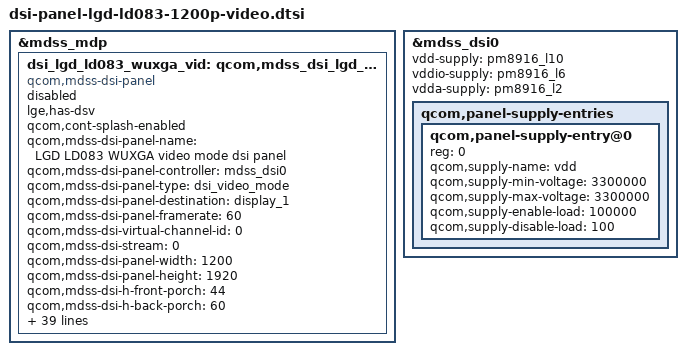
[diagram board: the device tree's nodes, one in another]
&mdss_mdp {
	dsi_lgd_ld083_wuxga_vid: qcom,mdss_dsi_lgd_ld083_wuxga_video{
		lge,has-dsv;
		compatible = "qcom,mdss-dsi-panel";
		status = "disable";
		qcom,cont-splash-enabled;
		qcom,mdss-dsi-panel-name = "LGD LD083 WUXGA video mode dsi panel";
		qcom,mdss-dsi-panel-controller = <&mdss_dsi0>;
		qcom,mdss-dsi-panel-type = "dsi_video_mode";
		qcom,mdss-dsi-panel-destination = "display_1";
		qcom,mdss-dsi-panel-framerate = <60>;
		qcom,mdss-dsi-virtual-channel-id = <0>;
		qcom,mdss-dsi-stream = <0>;
		qcom,mdss-dsi-panel-width = <1200>;
		qcom,mdss-dsi-panel-height = <1920>;
		qcom,mdss-dsi-h-front-porch = <44>;
		qcom,mdss-dsi-h-back-porch = <60>;
		qcom,mdss-dsi-h-pulse-width = <32>;
		qcom,mdss-dsi-h-sync-skew = <0>;
		qcom,mdss-dsi-v-back-porch = <10>;
		qcom,mdss-dsi-v-front-porch = <5>;
		qcom,mdss-dsi-v-pulse-width = <5>;
		qcom,mdss-dsi-h-left-border = <0>;
		qcom,mdss-dsi-h-right-border = <0>;
		qcom,mdss-dsi-v-top-border = <0>;
		qcom,mdss-dsi-v-bottom-border = <0>;
		qcom,mdss-pan-physical-width-dimension = < 111 >;
		qcom,mdss-pan-physical-height-dimension = < 178 >;
		qcom,mdss-dsi-bpp = <24>;
		qcom,mdss-dsi-color-order = "rgb_swap_rgb";
		qcom,mdss-dsi-underflow-color = <0xff>;
		qcom,mdss-dsi-border-color = <0>;
		qcom,mdss-dsi-on-command = [
			05 01 00 00 10 00 02
			11 00
			05 01 00 00 05 00 02
			29 00
		];
		lge,display-on-cmds = [
			05 01 00 00 10 00 02
			11 00
			05 01 00 00 05 00 02
			29 00
		];
		qcom,mdss-dsi-off-command = [
			05 01 00 00 05 00 02
			28 00
			05 01 00 00 0A 00 02
			10 00
		];
		qcom,mdss-dsi-on-command-state = "dsi_lp_mode";
		qcom,mdss-dsi-off-command-state = "dsi_hs_mode";
		qcom,mdss-dsi-h-sync-pulse = <0>;
		qcom,mdss-dsi-traffic-mode = "non_burst_sync_event";
		qcom,mdss-dsi-lane-map = "lane_map_0123";
		//qcom,mdss-dsi-hfp-power-mode;
		//qcom,mdss-dsi-hbp-power-mode;
		//qcom,mdss-dsi-hsa-power-mode;
		qcom,mdss-dsi-bllp-eof-power-mode;
		//qcom,mdss-dsi-bllp-power-mode;
		qcom,mdss-dsi-lane-0-state;
		qcom,mdss-dsi-lane-1-state;
		qcom,mdss-dsi-lane-2-state;
		qcom,mdss-dsi-lane-3-state;
		qcom,mdss-dsi-panel-timings = [EF 3A 28 00 6C FF 54 3E 61 03 04 00];
		qcom,mdss-dsi-t-clk-post = <0x02>;
		qcom,mdss-dsi-t-clk-pre = <0x32>;
		//qcom,mdss-dsi-bl-min-level = <1>;
		//qcom,mdss-dsi-bl-max-level = <4095>;
		qcom,mdss-dsi-dma-trigger = "trigger_sw";
		qcom,mdss-dsi-mdp-trigger = "none";
		//qcom,mdss-dsi-bl-pmic-control-type = "bl_ctrl_wled";
		qcom,mdss-dsi-reset-sequence = <1 20>, <0 20>, <1 20>;
	};
};


&mdss_dsi0 {
	vdd-supply = <&pm8916_l10>;
	vddio-supply = <&pm8916_l6>;
	vdda-supply = <&pm8916_l2>;
	qcom,panel-supply-entries {
		qcom,panel-supply-entry@0 {
			reg = <0>;
			qcom,supply-name = "vdd";
			qcom,supply-min-voltage = <3300000>;
			qcom,supply-max-voltage = <3300000>;
			qcom,supply-enable-load = <100000>;
			qcom,supply-disable-load = <100>;
		};
	};
};


